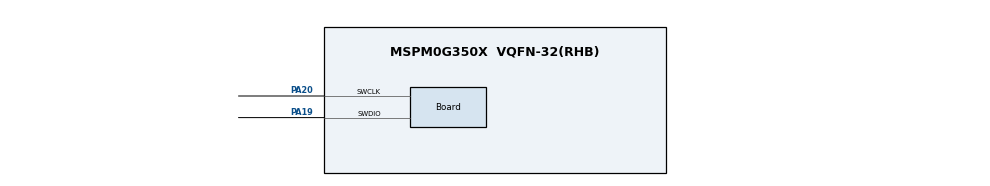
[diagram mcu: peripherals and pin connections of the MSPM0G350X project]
/**
 * @cliArgs --device "MSPM0G350X" --part "Default" --package "VQFN-32(RHB)" --product "mspm0_sdk@2.04.00.06"
 * @versions {"tool":"1.23.0+4000"}
 */

/**
 * Import the modules used in this configuration.
 */
const GPIO    = scripting.addModule("/ti/driverlib/GPIO", {}, false);
const GPIO1   = GPIO.addInstance();
const SYSCTL  = scripting.addModule("/ti/driverlib/SYSCTL");
const SYSTICK = scripting.addModule("/ti/driverlib/SYSTICK");

/**
 * Write custom configuration values to the imported modules.
 */
GPIO1.$name                              = "LED1";
GPIO1.associatedPins[0].$name            = "PIN1";
GPIO1.associatedPins[0].internalResistor = "PULL_UP";

const Board                       = scripting.addModule("/ti/driverlib/Board", {}, false);
Board.peripheral.$assign          = "DEBUGSS";
Board.peripheral.swclkPin.$assign = "PA20";
Board.peripheral.swdioPin.$assign = "PA19";

SYSCTL.forceDefaultClkConfig = true;
SYSCTL.clockTreeEn           = true;

SYSTICK.periodEnable    = true;
SYSTICK.systickEnable   = true;
SYSTICK.interruptEnable = true;
SYSTICK.period          = 32000;

const ProjectConfig              = scripting.addModule("/ti/project_config/ProjectConfig", {}, false);
ProjectConfig.migrationCondition = true;

/**
 * Pinmux solution for unlocked pins/peripherals. This ensures that minor changes to the automatic solver in a future
 * version of the tool will not impact the pinmux you originally saw.  These lines can be completely deleted in order to
 * re-solve from scratch.
 */
GPIO1.associatedPins[0].pin.$suggestSolution = "PA0";
